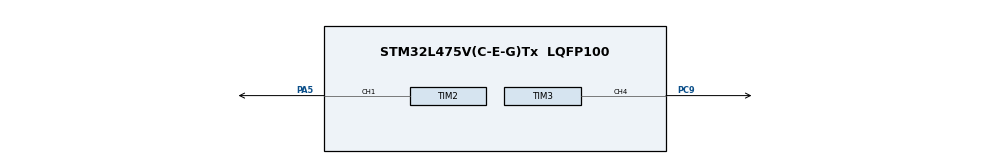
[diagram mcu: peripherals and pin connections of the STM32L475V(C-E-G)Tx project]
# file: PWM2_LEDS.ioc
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Mcu.Family=STM32L4
Mcu.Name=STM32L475V(C-E-G)Tx
Mcu.Package=LQFP100
NVIC.PriorityGroup=NVIC_PRIORITYGROUP_4
PA5.Signal=S_TIM2_CH1
PC9.Signal=S_TIM3_CH4
ProjectManager.HeapSize=0x200
ProjectManager.StackSize=0x400
ProjectManager.TargetToolchain=EWARM V8.32
RCC.HSE_VALUE=8000000
RCC.HSI_VALUE=16000000
RCC.LSE_VALUE=32768
RCC.MSI_VALUE=4000000
RCC.VCOOutputFreq_Value=32000000
SH.S_TIM2_CH1.0=TIM2_CH1,PWM Generation1 CH1
SH.S_TIM3_CH4.0=TIM3_CH4,PWM Generation4 CH4
TIM2.Channel-PWM\ Generation1\ CH1=TIM_CHANNEL_1
TIM2.Period=4000
TIM2.Pulse-PWM\ Generation1\ CH1=2000
TIM3.Channel-PWM\ Generation4\ CH4=TIM_CHANNEL_4
TIM3.Period=4000
TIM3.Pulse-PWM\ Generation4\ CH4=2000
VP_TIM2_VS_ClockSourceINT.Mode=Internal
VP_TIM3_VS_ClockSourceINT.Mode=Internal
board=custom

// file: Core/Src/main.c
/* USER CODE BEGIN Header */
/**
  ******************************************************************************
  * @file           : main.c
  * @brief          : Main program body
  ******************************************************************************
  * @attention
  *
  * <h2><center>&copy; Copyright (c) 2021 STMicroelectronics.
  * All rights reserved.</center></h2>
  *
  * This software component is licensed by ST under BSD 3-Clause license,
  * the "License"; You may not use this file except in compliance with the
  * License. You may obtain a copy of the License at:
  *                        opensource.org/licenses/BSD-3-Clause
  *
  ******************************************************************************
  */
/* USER CODE END Header */
#include "main.h"

TIM_HandleTypeDef htim2;
TIM_HandleTypeDef htim3;

static uint16_t pwm_value_TIM2 = 50;
static int16_t step_TIM2 = 0;
static uint16_t pwm_value_TIM3 = 3000;
static int16_t step_TIM3 = 0;

void SystemClock_Config(void);
static void MX_GPIO_Init(void);
static void MX_TIM2_Init(void);
static void MX_TIM3_Init(void);
/* USER CODE BEGIN PFP */
static void user_pwm_setvalue_TIM2(uint16_t value);
static void user_pwm_setvalue_TIM3(uint16_t value);

/* USER CODE END PFP */

int main(void)
{

  /* MCU Configuration--------------------------------------------------------*/

  /* Reset of all peripherals, Initializes the Flash interface and the Systick. */
  HAL_Init();

  /* Configure the system clock */
  SystemClock_Config();

  /* Initialize all configured peripherals */
  MX_GPIO_Init();
  MX_TIM2_Init();
  MX_TIM3_Init();
  /* USER CODE BEGIN 2 */
  HAL_TIM_PWM_Start(&htim2, TIM_CHANNEL_1);
  HAL_TIM_PWM_Start(&htim3, TIM_CHANNEL_4);
  /* USER CODE END 2 */

  /* Infinite loop */
  /* USER CODE BEGIN WHILE */
  static uint8_t DirectionFlg1 ='U';
  static uint8_t DirectionFlg3 ='D';
  while (1)
  {
    /* USER CODE END WHILE */

    /* USER CODE BEGIN 3 */
    HAL_Delay(15);
/*== Control LED 1 brightness with PWM ==*/
    if (DirectionFlg1 == 'U')
    { // Crude compensation for nonlinearity of LED 1 brightness
      if(pwm_value_TIM2 == 50) step_TIM2 = 25;
      if(pwm_value_TIM2 == 1000) step_TIM2 = 100;
      if(pwm_value_TIM2 == 2000) step_TIM2 = 200;
      pwm_value_TIM2 += step_TIM2;
      if(pwm_value_TIM2 == 3000) DirectionFlg1 = 'D';
    }
    else
    { // Crude compensation for nonlinearity of LED 1 brightness
      if(pwm_value_TIM2 == 3000) step_TIM2 = -200;
      if(pwm_value_TIM2 == 2000) step_TIM2 = -100;
      if(pwm_value_TIM2 == 1000) step_TIM2 = -25;
      pwm_value_TIM2 += step_TIM2;
      if(pwm_value_TIM2 == 50) DirectionFlg1 = 'U';
    }
//  pwm_value_TIM2 += step_TIM2;
    user_pwm_setvalue_TIM2(pwm_value_TIM2);

/*== Control LED 3 brightness with PWM ==*/

    if (DirectionFlg3 == 'U')
    { // Crude compensation for nonlinearity of LED 3 brightness
      if(pwm_value_TIM3 == 100) step_TIM3 = 25;
      if(pwm_value_TIM3 == 1000) step_TIM3 = 100;
      if(pwm_value_TIM3 == 2000) step_TIM3 = 200;
      pwm_value_TIM3 += step_TIM3;
      if(pwm_value_TIM3 == 3000) DirectionFlg3 = 'D';
    }
    else
    { // Crude compensation for nonlinearity of LED 3 brightness
      if(pwm_value_TIM3 == 3000) step_TIM3 = -200;
      if(pwm_value_TIM3 == 2000) step_TIM3 = -100;
      if(pwm_value_TIM3 == 1000) step_TIM3 = -25;
      pwm_value_TIM3 += step_TIM3;
      if(pwm_value_TIM3 == 100) DirectionFlg3 = 'U';
    }

// if(pwm_value_TIM3 == 50) step_TIM3 = 50;
// if(pwm_value_TIM3 == 2000) step_TIM3 = -50;
//  pwm_value_TIM3 += step_TIM3;
    user_pwm_setvalue_TIM3(pwm_value_TIM3);
  }
  /* USER CODE END 3 */
}

void SystemClock_Config(void)
{
  RCC_OscInitTypeDef RCC_OscInitStruct = {0};
  RCC_ClkInitTypeDef RCC_ClkInitStruct = {0};

  /** Configure the main internal regulator output voltage
  */
  if (HAL_PWREx_ControlVoltageScaling(PWR_REGULATOR_VOLTAGE_SCALE1) != HAL_OK)
  {
    Error_Handler();
  }
  /** Initializes the RCC Oscillators according to the specified parameters
  * in the RCC_OscInitTypeDef structure.
  */
  RCC_OscInitStruct.OscillatorType = RCC_OSCILLATORTYPE_MSI;
  RCC_OscInitStruct.MSIState = RCC_MSI_ON;
  RCC_OscInitStruct.MSICalibrationValue = 0;
  RCC_OscInitStruct.MSIClockRange = RCC_MSIRANGE_6;
  RCC_OscInitStruct.PLL.PLLState = RCC_PLL_NONE;
  if (HAL_RCC_OscConfig(&RCC_OscInitStruct) != HAL_OK)
  {
    Error_Handler();
  }
  /** Initializes the CPU, AHB and APB buses clocks
  */
  RCC_ClkInitStruct.ClockType = RCC_CLOCKTYPE_HCLK|RCC_CLOCKTYPE_SYSCLK
                              |RCC_CLOCKTYPE_PCLK1|RCC_CLOCKTYPE_PCLK2;
  RCC_ClkInitStruct.SYSCLKSource = RCC_SYSCLKSOURCE_MSI;
  RCC_ClkInitStruct.AHBCLKDivider = RCC_SYSCLK_DIV1;
  RCC_ClkInitStruct.APB1CLKDivider = RCC_HCLK_DIV1;
  RCC_ClkInitStruct.APB2CLKDivider = RCC_HCLK_DIV1;

  if (HAL_RCC_ClockConfig(&RCC_ClkInitStruct, FLASH_LATENCY_0) != HAL_OK)
  {
    Error_Handler();
  }
}

static void MX_TIM2_Init(void)
{

  TIM_ClockConfigTypeDef sClockSourceConfig = {0};
  TIM_MasterConfigTypeDef sMasterConfig = {0};
  TIM_OC_InitTypeDef sConfigOC = {0};

  htim2.Instance = TIM2;
  htim2.Init.Prescaler = 0;
  htim2.Init.CounterMode = TIM_COUNTERMODE_UP;
  htim2.Init.Period = 4000;
  htim2.Init.ClockDivision = TIM_CLOCKDIVISION_DIV1;
  htim2.Init.AutoReloadPreload = TIM_AUTORELOAD_PRELOAD_DISABLE;
  if (HAL_TIM_Base_Init(&htim2) != HAL_OK)
  {
    Error_Handler();
  }
  sClockSourceConfig.ClockSource = TIM_CLOCKSOURCE_INTERNAL;
  if (HAL_TIM_ConfigClockSource(&htim2, &sClockSourceConfig) != HAL_OK)
  {
    Error_Handler();
  }
  if (HAL_TIM_PWM_Init(&htim2) != HAL_OK)
  {
    Error_Handler();
  }
  sMasterConfig.MasterOutputTrigger = TIM_TRGO_RESET;
  sMasterConfig.MasterSlaveMode = TIM_MASTERSLAVEMODE_DISABLE;
  if (HAL_TIMEx_MasterConfigSynchronization(&htim2, &sMasterConfig) != HAL_OK)
  {
    Error_Handler();
  }
  sConfigOC.OCMode = TIM_OCMODE_PWM1;
  sConfigOC.Pulse = 2000;
  sConfigOC.OCPolarity = TIM_OCPOLARITY_HIGH;
  sConfigOC.OCFastMode = TIM_OCFAST_DISABLE;
  if (HAL_TIM_PWM_ConfigChannel(&htim2, &sConfigOC, TIM_CHANNEL_1) != HAL_OK)
  {
    Error_Handler();
  }
  HAL_TIM_MspPostInit(&htim2);

}

static void MX_TIM3_Init(void)
{

  TIM_ClockConfigTypeDef sClockSourceConfig = {0};
  TIM_MasterConfigTypeDef sMasterConfig = {0};
  TIM_OC_InitTypeDef sConfigOC = {0};

  htim3.Instance = TIM3;
  htim3.Init.Prescaler = 0;
  htim3.Init.CounterMode = TIM_COUNTERMODE_UP;
  htim3.Init.Period = 4000;
  htim3.Init.ClockDivision = TIM_CLOCKDIVISION_DIV1;
  htim3.Init.AutoReloadPreload = TIM_AUTORELOAD_PRELOAD_DISABLE;
  if (HAL_TIM_Base_Init(&htim3) != HAL_OK)
  {
    Error_Handler();
  }
  sClockSourceConfig.ClockSource = TIM_CLOCKSOURCE_INTERNAL;
  if (HAL_TIM_ConfigClockSource(&htim3, &sClockSourceConfig) != HAL_OK)
  {
    Error_Handler();
  }
  if (HAL_TIM_PWM_Init(&htim3) != HAL_OK)
  {
    Error_Handler();
  }
  sMasterConfig.MasterOutputTrigger = TIM_TRGO_RESET;
  sMasterConfig.MasterSlaveMode = TIM_MASTERSLAVEMODE_DISABLE;
  if (HAL_TIMEx_MasterConfigSynchronization(&htim3, &sMasterConfig) != HAL_OK)
  {
    Error_Handler();
  }
  sConfigOC.OCMode = TIM_OCMODE_PWM1;
  sConfigOC.Pulse = 2000;
  sConfigOC.OCPolarity = TIM_OCPOLARITY_HIGH;
  sConfigOC.OCFastMode = TIM_OCFAST_DISABLE;
  if (HAL_TIM_PWM_ConfigChannel(&htim3, &sConfigOC, TIM_CHANNEL_4) != HAL_OK)
  {
    Error_Handler();
  }
  HAL_TIM_MspPostInit(&htim3);

}

static void MX_GPIO_Init(void)
{

  /* GPIO Ports Clock Enable */
  __HAL_RCC_GPIOA_CLK_ENABLE();
  __HAL_RCC_GPIOC_CLK_ENABLE();

}

/* USER CODE BEGIN 4 */
static void user_pwm_setvalue_TIM2(uint16_t value)
{
  HAL_TIM_PWM_Stop(&htim2, TIM_CHANNEL_1);

  TIM_OC_InitTypeDef sConfigOC = {0};
  sConfigOC.OCMode = TIM_OCMODE_PWM1;
  sConfigOC.Pulse = value;
  sConfigOC.OCPolarity = TIM_OCPOLARITY_HIGH;
  sConfigOC.OCFastMode = TIM_OCFAST_DISABLE;
  if (HAL_TIM_PWM_ConfigChannel(&htim2, &sConfigOC, TIM_CHANNEL_1) != HAL_OK)
  {
    Error_Handler();
  }

  HAL_TIM_PWM_Start(&htim2, TIM_CHANNEL_1);
}

static void user_pwm_setvalue_TIM3(uint16_t value)
{
  HAL_TIM_PWM_Stop(&htim3, TIM_CHANNEL_4);

  TIM_OC_InitTypeDef sConfigOC = {0};
  sConfigOC.OCMode = TIM_OCMODE_PWM1;
  sConfigOC.Pulse = value;
  sConfigOC.OCPolarity = TIM_OCPOLARITY_HIGH;
  sConfigOC.OCFastMode = TIM_OCFAST_DISABLE;
  if (HAL_TIM_PWM_ConfigChannel(&htim3, &sConfigOC, TIM_CHANNEL_4) != HAL_OK)
  {
    Error_Handler();
  }

  HAL_TIM_PWM_Start(&htim3, TIM_CHANNEL_4);
}
/* USER CODE END 4 */

void Error_Handler(void)
{
  __disable_irq();
  while (1)
  {
  }
}

/************************ (C) COPYRIGHT STMicroelectronics *****END OF FILE****/
